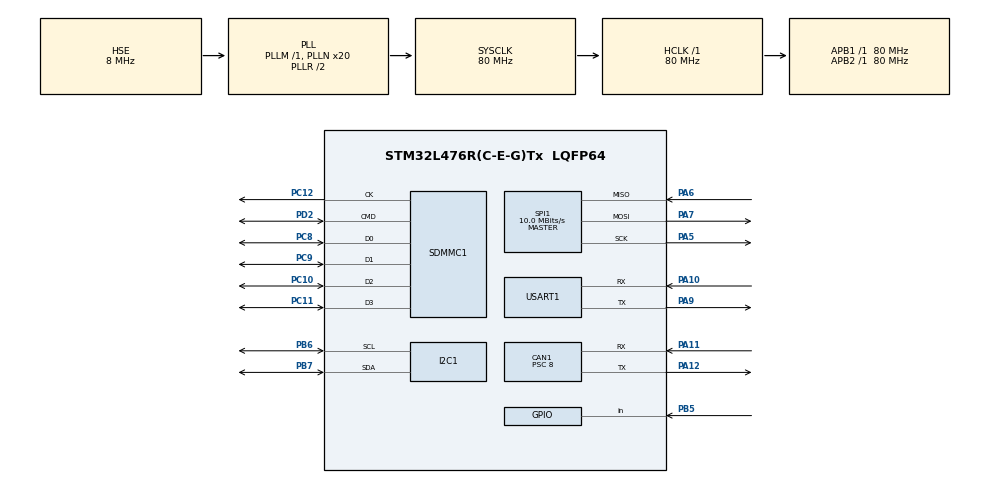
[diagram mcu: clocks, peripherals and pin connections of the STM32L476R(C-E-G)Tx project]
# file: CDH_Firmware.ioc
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CAN1.BS1=CAN_BS1_12TQ
CAN1.BS2=CAN_BS2_3TQ
CAN1.CalculateBaudRate=625000
CAN1.CalculateTimeBit=1600
CAN1.CalculateTimeQuantum=100.0
CAN1.NART=ENABLE
CAN1.Prescaler=8
FATFS.BSP.number=1
FATFS0.BSP.STBoard=false
FATFS0.BSP.api=Unknown
FATFS0.BSP.i2caddr=0
FATFS0.BSP.instance=PB5
FATFS0.BSP.ip=GPIO
FATFS0.BSP.mode=Input
FATFS0.BSP.name=Detect_SDIO
FATFS0.BSP.solution=PB5
FREERTOS.Mutexes01=Config_Mutex,Static,Config_MutexControlBlock;UART_Mutex,Static,UART_MutexControlBlock
FREERTOS.Queues01=CAN_Queue,10,CAN_Event_t,0,Static,CAN_QueueBuffer,CAN_QueueControlBlock;Radio_Queue,8,radio_event_t,0,Static,Radio_QueueBuffer,Radio_QueueControlBlock;GPS_Queue,2,gps_event_t,0,Static,GPS_QueueBuffer,GPS_QueueControlBlock;OBC_Fragment_Queue,8,fragment_t,0,Static,OBC_Fragment_QueueBuffer,OBC_Fragment_QueueControlBlock;RAS_Fragment_Queue,14,fragment_t,0,Static,RAS_Fragment_QueueBuffer,RAS_Fragment_QueueControlBlock;OBC_Blob_Queue,4,obc_blob_t,0,Static,OBC_Blob_QueueBuffer,OBC_Blob_QueueControlBlock;RAS_Blob_Queue,14,ras_blob_t,0,Static,RAS_Blob_QueueBuffer,RAS_Blob_QueueControlBlock
FREERTOS.Tasks01=defaultTask,24,256,StartDefaultTask,Default,NULL,Static,defaultTaskBuffer,defaultTaskControlBlock;CAN_Task,32,256,CAN_TaskFun,As external,NULL,Static,CAN_TaskBuffer,CAN_TaskControlBlock;GPS_Task,8,256,GPS_TaskFun,As external,NULL,Static,GPS_TaskBuffer,GPS_TaskControlBlock;RAS_Blob_Task,8,256,RAS_Blob_TaskFun,As external,NULL,Static,RAS_Blob_TaskBuffer,RAS_Blob_TaskControlBlock;OBC_Blob_Task,8,256,OBC_Blob_TaskFun,As external,NULL,Static,OBC_Blob_TaskBuffer,OBC_Blob_TaskControlBlock;Storage_Task,8,256,Storage_TaskFun,As external,NULL,Static,Storage_TaskBuffer,Storage_TaskControlBlock;PktBuilder_Task,8,256,PktBuilder_TaskFun,As external,NULL,Static,PktBuilder_TaskBuffer,PktBuilder_TaskControlBlock;Radio_Task,8,256,Radio_TaskFun,As external,NULL,Static,Radio_TaskBuffer,Radio_TaskControlBlock;Stimulus_Task,8,256,Stimulus_TaskFun,As external,NULL,Static,Stimulus_TaskBuffer,Stimulus_TaskControlBlock
FREERTOS.Timers01=OBC_Timer,OBC_TimerFun,osTimerPeriodic,As external,NULL,Static,OBC_TimerControlBlock;RAS_Timer,RAS_TimerFun,osTimerPeriodic,As external,NULL,Static,RAS_TimerControlBlock;Radio_Timer,Radio_TimerFun,osTimerPeriodic,As external,NULL,Static,Radio_TimerControlBlock;GPS_Timer,GPS_TimerFun,osTimerPeriodic,As external,NULL,Static,GPS_TimerControlBlock
FREERTOS.configMINIMAL_STACK_SIZE=256
FREERTOS.configUSE_NEWLIB_REENTRANT=1
FREERTOS.configUSE_TICKLESS_IDLE=1
I2C1.Timing=0x10909CEC
Mcu.Family=STM32L4
Mcu.Name=STM32L476R(C-E-G)Tx
Mcu.Package=LQFP64
NVIC.CAN1_RX0_IRQn=true\:5\:0\:false\:false\:true\:true\:true\:true
NVIC.CAN1_TX_IRQn=true\:5\:0\:false\:false\:true\:true\:true\:true
NVIC.PriorityGroup=NVIC_PRIORITYGROUP_4
PA10.Mode=Asynchronous
PA10.Signal=USART1_RX
PA11.Mode=CAN_Activate
PA11.Signal=CAN1_RX
PA12.Mode=CAN_Activate
PA12.Signal=CAN1_TX
PA13\ (JTMS-SWDIO).Mode=Serial_Wire
PA13\ (JTMS-SWDIO).Signal=SYS_JTMS-SWDIO
PA14\ (JTCK-SWCLK).Mode=Serial_Wire
PA14\ (JTCK-SWCLK).Signal=SYS_JTCK-SWCLK
PA5.Mode=Full_Duplex_Master
PA5.Signal=SPI1_SCK
PA6.Mode=Full_Duplex_Master
PA6.Signal=SPI1_MISO
PA7.Mode=Full_Duplex_Master
PA7.Signal=SPI1_MOSI
PA9.Mode=Asynchronous
PA9.Signal=USART1_TX
PB5.Signal=GPIO_Input
PB6.Mode=I2C
PB6.Signal=I2C1_SCL
PB7.Mode=I2C
PB7.Signal=I2C1_SDA
PC10.Mode=SD_4_bits_Wide_bus
PC10.Signal=SDMMC1_D2
PC11.Mode=SD_4_bits_Wide_bus
PC11.Signal=SDMMC1_D3
PC12.Mode=SD_4_bits_Wide_bus
PC12.Signal=SDMMC1_CK
PC14-OSC32_IN\ (PC14).Mode=LSE-External-Oscillator
PC14-OSC32_IN\ (PC14).Signal=RCC_OSC32_IN
PC15-OSC32_OUT\ (PC15).Mode=LSE-External-Oscillator
PC15-OSC32_OUT\ (PC15).Signal=RCC_OSC32_OUT
PC8.Mode=SD_4_bits_Wide_bus
PC8.Signal=SDMMC1_D0
PC9.Mode=SD_4_bits_Wide_bus
PC9.Signal=SDMMC1_D1
PD2.Mode=SD_4_bits_Wide_bus
PD2.Signal=SDMMC1_CMD
PH0-OSC_IN\ (PH0).Mode=HSE-External-Oscillator
PH0-OSC_IN\ (PH0).Signal=RCC_OSC_IN
PH1-OSC_OUT\ (PH1).Mode=HSE-External-Oscillator
PH1-OSC_OUT\ (PH1).Signal=RCC_OSC_OUT
ProjectManager.HeapSize=0x200
ProjectManager.StackSize=0x400
ProjectManager.TargetToolchain=STM32CubeIDE
RCC.ADCFreq_Value=32000000
RCC.AHBFreq_Value=80000000
RCC.APB1Freq_Value=80000000
RCC.APB1TimFreq_Value=80000000
RCC.APB2Freq_Value=80000000
RCC.APB2TimFreq_Value=80000000
RCC.CortexFreq_Value=80000000
RCC.EnableCSSLSE=true
RCC.EnbaleCSS=true
RCC.HCLKFreq_Value=80000000
RCC.HSE_VALUE=8000000
RCC.HSI_VALUE=16000000
RCC.MSI_VALUE=4000000
RCC.PLLN=20
RCC.PLLSourceVirtual=RCC_PLLSOURCE_HSE
RCC.RTCClockSelection=RCC_RTCCLKSOURCE_LSE
RCC.SYSCLKFreq_VALUE=80000000
RCC.SYSCLKSource=RCC_SYSCLKSOURCE_PLLCLK
RCC.USBFreq_Value=32000000
RCC.VCOOutputFreq_Value=160000000
SPI1.BaudRatePrescaler=SPI_BAUDRATEPRESCALER_8
SPI1.CalculateBaudRate=10.0 MBits/s
SPI1.Direction=SPI_DIRECTION_2LINES
SPI1.Mode=SPI_MODE_MASTER
SPI1.VirtualType=VM_MASTER
USART1.VirtualMode-Asynchronous=VM_ASYNC
VP_FATFS_VS_SDIO.Mode=SDIO
VP_FREERTOS_VS_CMSIS_V2.Mode=CMSIS_V2
VP_RTC_VS_RTC_Activate.Mode=RTC_Enabled
board=custom

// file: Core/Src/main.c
/* USER CODE BEGIN Header */
/**
  ******************************************************************************
  * @file           : main.c
  * @brief          : Main program body
  ******************************************************************************
  * @attention
  *
  * Copyright (c) 2022 STMicroelectronics.
  * All rights reserved.
  *
  * This software is licensed under terms that can be found in the LICENSE file
  * in the root directory of this software component.
  * If no LICENSE file comes with this software, it is provided AS-IS.
  *
  ******************************************************************************
  */
/* USER CODE END Header */
#include "main.h"
#include "cmsis_os.h"
#include "can.h"
#include "fatfs.h"
#include "i2c.h"
#include "rtc.h"
#include "sdmmc.h"
#include "spi.h"
#include "usart.h"
#include "gpio.h"

void SystemClock_Config(void);
void MX_FREERTOS_Init(void);

int main(void)
{

  /* MCU Configuration--------------------------------------------------------*/

  /* Reset of all peripherals, Initializes the Flash interface and the Systick. */
  HAL_Init();

  /* Configure the system clock */
  SystemClock_Config();

  /* Initialize all configured peripherals */
  MX_GPIO_Init();
  MX_RTC_Init();
  MX_CAN1_Init();
  MX_I2C1_Init();
  MX_SDMMC1_SD_Init();
  MX_SPI1_Init();
  MX_USART1_UART_Init();
  MX_FATFS_Init();

  /* Init scheduler */
  osKernelInitialize();  /* Call init function for freertos objects (in freertos.c) */
  MX_FREERTOS_Init();
  /* Start scheduler */
  osKernelStart();

  /* We should never get here as control is now taken by the scheduler */
  /* Infinite loop */
  while (1)
  {

  }
}

void SystemClock_Config(void)
{
  RCC_OscInitTypeDef RCC_OscInitStruct = {0};
  RCC_ClkInitTypeDef RCC_ClkInitStruct = {0};

  /** Configure the main internal regulator output voltage
  */
  if (HAL_PWREx_ControlVoltageScaling(PWR_REGULATOR_VOLTAGE_SCALE1) != HAL_OK)
  {
    Error_Handler();
  }
  /** Configure LSE Drive Capability
  */
  HAL_PWR_EnableBkUpAccess();
  __HAL_RCC_LSEDRIVE_CONFIG(RCC_LSEDRIVE_LOW);
  /** Initializes the RCC Oscillators according to the specified parameters
  * in the RCC_OscInitTypeDef structure.
  */
  RCC_OscInitStruct.OscillatorType = RCC_OSCILLATORTYPE_HSE|RCC_OSCILLATORTYPE_LSE;
  RCC_OscInitStruct.HSEState = RCC_HSE_ON;
  RCC_OscInitStruct.LSEState = RCC_LSE_ON;
  RCC_OscInitStruct.PLL.PLLState = RCC_PLL_ON;
  RCC_OscInitStruct.PLL.PLLSource = RCC_PLLSOURCE_HSE;
  RCC_OscInitStruct.PLL.PLLM = 1;
  RCC_OscInitStruct.PLL.PLLN = 20;
  RCC_OscInitStruct.PLL.PLLP = RCC_PLLP_DIV7;
  RCC_OscInitStruct.PLL.PLLQ = RCC_PLLQ_DIV2;
  RCC_OscInitStruct.PLL.PLLR = RCC_PLLR_DIV2;
  if (HAL_RCC_OscConfig(&RCC_OscInitStruct) != HAL_OK)
  {
    Error_Handler();
  }
  /** Initializes the CPU, AHB and APB buses clocks
  */
  RCC_ClkInitStruct.ClockType = RCC_CLOCKTYPE_HCLK|RCC_CLOCKTYPE_SYSCLK
                              |RCC_CLOCKTYPE_PCLK1|RCC_CLOCKTYPE_PCLK2;
  RCC_ClkInitStruct.SYSCLKSource = RCC_SYSCLKSOURCE_PLLCLK;
  RCC_ClkInitStruct.AHBCLKDivider = RCC_SYSCLK_DIV1;
  RCC_ClkInitStruct.APB1CLKDivider = RCC_HCLK_DIV1;
  RCC_ClkInitStruct.APB2CLKDivider = RCC_HCLK_DIV1;

  if (HAL_RCC_ClockConfig(&RCC_ClkInitStruct, FLASH_LATENCY_4) != HAL_OK)
  {
    Error_Handler();
  }
  /** Enables the Clock Security System
  */
  HAL_RCC_EnableCSS();
  /** Enables the Clock Security System
  */
  HAL_RCCEx_EnableLSECSS();
}

void Error_Handler(void)
{
  __disable_irq();
  while (1)
  {
  }
}

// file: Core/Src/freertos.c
/* USER CODE BEGIN Header */
/**
  ******************************************************************************
  * File Name          : freertos.c
  * Description        : Code for freertos applications
  ******************************************************************************
  * @attention
  *
  * Copyright (c) 2022 STMicroelectronics.
  * All rights reserved.
  *
  * This software is licensed under terms that can be found in the LICENSE file
  * in the root directory of this software component.
  * If no LICENSE file comes with this software, it is provided AS-IS.
  *
  ******************************************************************************
  */
/* USER CODE END Header */

#include "FreeRTOS.h"
#include "task.h"
#include "main.h"
#include "cmsis_os.h"

/* USER CODE BEGIN Includes */
#include "CDH.h"
/* USER CODE END Includes */

typedef StaticTask_t osStaticThreadDef_t;
typedef StaticQueue_t osStaticMessageQDef_t;
typedef StaticTimer_t osStaticTimerDef_t;
typedef StaticSemaphore_t osStaticMutexDef_t;

/* Definitions for defaultTask */
osThreadId_t defaultTaskHandle;
uint32_t defaultTaskBuffer[ 256 ];
osStaticThreadDef_t defaultTaskControlBlock;
const osThreadAttr_t defaultTask_attributes = {
  .name = "defaultTask",
  .cb_mem = &defaultTaskControlBlock,
  .cb_size = sizeof(defaultTaskControlBlock),
  .stack_mem = &defaultTaskBuffer[0],
  .stack_size = sizeof(defaultTaskBuffer),
  .priority = (osPriority_t) osPriorityNormal,
};
/* Definitions for CAN_Task */
osThreadId_t CAN_TaskHandle;
uint32_t CAN_TaskBuffer[ 256 ];
osStaticThreadDef_t CAN_TaskControlBlock;
const osThreadAttr_t CAN_Task_attributes = {
  .name = "CAN_Task",
  .cb_mem = &CAN_TaskControlBlock,
  .cb_size = sizeof(CAN_TaskControlBlock),
  .stack_mem = &CAN_TaskBuffer[0],
  .stack_size = sizeof(CAN_TaskBuffer),
  .priority = (osPriority_t) osPriorityAboveNormal,
};
/* Definitions for GPS_Task */
osThreadId_t GPS_TaskHandle;
uint32_t GPS_TaskBuffer[ 256 ];
osStaticThreadDef_t GPS_TaskControlBlock;
const osThreadAttr_t GPS_Task_attributes = {
  .name = "GPS_Task",
  .cb_mem = &GPS_TaskControlBlock,
  .cb_size = sizeof(GPS_TaskControlBlock),
  .stack_mem = &GPS_TaskBuffer[0],
  .stack_size = sizeof(GPS_TaskBuffer),
  .priority = (osPriority_t) osPriorityLow,
};
/* Definitions for RAS_Blob_Task */
osThreadId_t RAS_Blob_TaskHandle;
uint32_t RAS_Blob_TaskBuffer[ 256 ];
osStaticThreadDef_t RAS_Blob_TaskControlBlock;
const osThreadAttr_t RAS_Blob_Task_attributes = {
  .name = "RAS_Blob_Task",
  .cb_mem = &RAS_Blob_TaskControlBlock,
  .cb_size = sizeof(RAS_Blob_TaskControlBlock),
  .stack_mem = &RAS_Blob_TaskBuffer[0],
  .stack_size = sizeof(RAS_Blob_TaskBuffer),
  .priority = (osPriority_t) osPriorityLow,
};
/* Definitions for OBC_Blob_Task */
osThreadId_t OBC_Blob_TaskHandle;
uint32_t OBC_Blob_TaskBuffer[ 256 ];
osStaticThreadDef_t OBC_Blob_TaskControlBlock;
const osThreadAttr_t OBC_Blob_Task_attributes = {
  .name = "OBC_Blob_Task",
  .cb_mem = &OBC_Blob_TaskControlBlock,
  .cb_size = sizeof(OBC_Blob_TaskControlBlock),
  .stack_mem = &OBC_Blob_TaskBuffer[0],
  .stack_size = sizeof(OBC_Blob_TaskBuffer),
  .priority = (osPriority_t) osPriorityLow,
};
/* Definitions for Storage_Task */
osThreadId_t Storage_TaskHandle;
uint32_t Storage_TaskBuffer[ 256 ];
osStaticThreadDef_t Storage_TaskControlBlock;
const osThreadAttr_t Storage_Task_attributes = {
  .name = "Storage_Task",
  .cb_mem = &Storage_TaskControlBlock,
  .cb_size = sizeof(Storage_TaskControlBlock),
  .stack_mem = &Storage_TaskBuffer[0],
  .stack_size = sizeof(Storage_TaskBuffer),
  .priority = (osPriority_t) osPriorityLow,
};
/* Definitions for PktBuilder_Task */
osThreadId_t PktBuilder_TaskHandle;
uint32_t PktBuilder_TaskBuffer[ 256 ];
osStaticThreadDef_t PktBuilder_TaskControlBlock;
const osThreadAttr_t PktBuilder_Task_attributes = {
  .name = "PktBuilder_Task",
  .cb_mem = &PktBuilder_TaskControlBlock,
  .cb_size = sizeof(PktBuilder_TaskControlBlock),
  .stack_mem = &PktBuilder_TaskBuffer[0],
  .stack_size = sizeof(PktBuilder_TaskBuffer),
  .priority = (osPriority_t) osPriorityLow,
};
/* Definitions for Radio_Task */
osThreadId_t Radio_TaskHandle;
uint32_t Radio_TaskBuffer[ 256 ];
osStaticThreadDef_t Radio_TaskControlBlock;
const osThreadAttr_t Radio_Task_attributes = {
  .name = "Radio_Task",
  .cb_mem = &Radio_TaskControlBlock,
  .cb_size = sizeof(Radio_TaskControlBlock),
  .stack_mem = &Radio_TaskBuffer[0],
  .stack_size = sizeof(Radio_TaskBuffer),
  .priority = (osPriority_t) osPriorityLow,
};
/* Definitions for Stimulus_Task */
osThreadId_t Stimulus_TaskHandle;
uint32_t Stimulus_TaskBuffer[ 256 ];
osStaticThreadDef_t Stimulus_TaskControlBlock;
const osThreadAttr_t Stimulus_Task_attributes = {
  .name = "Stimulus_Task",
  .cb_mem = &Stimulus_TaskControlBlock,
  .cb_size = sizeof(Stimulus_TaskControlBlock),
  .stack_mem = &Stimulus_TaskBuffer[0],
  .stack_size = sizeof(Stimulus_TaskBuffer),
  .priority = (osPriority_t) osPriorityLow,
};
/* Definitions for CAN_Queue */
osMessageQueueId_t CAN_QueueHandle;
uint8_t CAN_QueueBuffer[ 10 * sizeof( CAN_Event_t ) ];
osStaticMessageQDef_t CAN_QueueControlBlock;
const osMessageQueueAttr_t CAN_Queue_attributes = {
  .name = "CAN_Queue",
  .cb_mem = &CAN_QueueControlBlock,
  .cb_size = sizeof(CAN_QueueControlBlock),
  .mq_mem = &CAN_QueueBuffer,
  .mq_size = sizeof(CAN_QueueBuffer)
};
/* Definitions for Radio_Queue */
osMessageQueueId_t Radio_QueueHandle;
uint8_t Radio_QueueBuffer[ 8 * sizeof( radio_event_t ) ];
osStaticMessageQDef_t Radio_QueueControlBlock;
const osMessageQueueAttr_t Radio_Queue_attributes = {
  .name = "Radio_Queue",
  .cb_mem = &Radio_QueueControlBlock,
  .cb_size = sizeof(Radio_QueueControlBlock),
  .mq_mem = &Radio_QueueBuffer,
  .mq_size = sizeof(Radio_QueueBuffer)
};
/* Definitions for GPS_Queue */
osMessageQueueId_t GPS_QueueHandle;
uint8_t GPS_QueueBuffer[ 2 * sizeof( gps_event_t ) ];
osStaticMessageQDef_t GPS_QueueControlBlock;
const osMessageQueueAttr_t GPS_Queue_attributes = {
  .name = "GPS_Queue",
  .cb_mem = &GPS_QueueControlBlock,
  .cb_size = sizeof(GPS_QueueControlBlock),
  .mq_mem = &GPS_QueueBuffer,
  .mq_size = sizeof(GPS_QueueBuffer)
};
/* Definitions for OBC_Fragment_Queue */
osMessageQueueId_t OBC_Fragment_QueueHandle;
uint8_t OBC_Fragment_QueueBuffer[ 8 * sizeof( fragment_t ) ];
osStaticMessageQDef_t OBC_Fragment_QueueControlBlock;
const osMessageQueueAttr_t OBC_Fragment_Queue_attributes = {
  .name = "OBC_Fragment_Queue",
  .cb_mem = &OBC_Fragment_QueueControlBlock,
  .cb_size = sizeof(OBC_Fragment_QueueControlBlock),
  .mq_mem = &OBC_Fragment_QueueBuffer,
  .mq_size = sizeof(OBC_Fragment_QueueBuffer)
};
/* Definitions for RAS_Fragment_Queue */
osMessageQueueId_t RAS_Fragment_QueueHandle;
uint8_t RAS_Fragment_QueueBuffer[ 14 * sizeof( fragment_t ) ];
osStaticMessageQDef_t RAS_Fragment_QueueControlBlock;
const osMessageQueueAttr_t RAS_Fragment_Queue_attributes = {
  .name = "RAS_Fragment_Queue",
  .cb_mem = &RAS_Fragment_QueueControlBlock,
  .cb_size = sizeof(RAS_Fragment_QueueControlBlock),
  .mq_mem = &RAS_Fragment_QueueBuffer,
  .mq_size = sizeof(RAS_Fragment_QueueBuffer)
};
/* Definitions for OBC_Blob_Queue */
osMessageQueueId_t OBC_Blob_QueueHandle;
uint8_t OBC_Blob_QueueBuffer[ 4 * sizeof( obc_blob_t ) ];
osStaticMessageQDef_t OBC_Blob_QueueControlBlock;
const osMessageQueueAttr_t OBC_Blob_Queue_attributes = {
  .name = "OBC_Blob_Queue",
  .cb_mem = &OBC_Blob_QueueControlBlock,
  .cb_size = sizeof(OBC_Blob_QueueControlBlock),
  .mq_mem = &OBC_Blob_QueueBuffer,
  .mq_size = sizeof(OBC_Blob_QueueBuffer)
};
/* Definitions for RAS_Blob_Queue */
osMessageQueueId_t RAS_Blob_QueueHandle;
uint8_t RAS_Blob_QueueBuffer[ 14 * sizeof( ras_blob_t ) ];
osStaticMessageQDef_t RAS_Blob_QueueControlBlock;
const osMessageQueueAttr_t RAS_Blob_Queue_attributes = {
  .name = "RAS_Blob_Queue",
  .cb_mem = &RAS_Blob_QueueControlBlock,
  .cb_size = sizeof(RAS_Blob_QueueControlBlock),
  .mq_mem = &RAS_Blob_QueueBuffer,
  .mq_size = sizeof(RAS_Blob_QueueBuffer)
};
/* Definitions for OBC_Timer */
osTimerId_t OBC_TimerHandle;
osStaticTimerDef_t OBC_TimerControlBlock;
const osTimerAttr_t OBC_Timer_attributes = {
  .name = "OBC_Timer",
  .cb_mem = &OBC_TimerControlBlock,
  .cb_size = sizeof(OBC_TimerControlBlock),
};
/* Definitions for RAS_Timer */
osTimerId_t RAS_TimerHandle;
osStaticTimerDef_t RAS_TimerControlBlock;
const osTimerAttr_t RAS_Timer_attributes = {
  .name = "RAS_Timer",
  .cb_mem = &RAS_TimerControlBlock,
  .cb_size = sizeof(RAS_TimerControlBlock),
};
/* Definitions for Radio_Timer */
osTimerId_t Radio_TimerHandle;
osStaticTimerDef_t Radio_TimerControlBlock;
const osTimerAttr_t Radio_Timer_attributes = {
  .name = "Radio_Timer",
  .cb_mem = &Radio_TimerControlBlock,
  .cb_size = sizeof(Radio_TimerControlBlock),
};
/* Definitions for GPS_Timer */
osTimerId_t GPS_TimerHandle;
osStaticTimerDef_t GPS_TimerControlBlock;
const osTimerAttr_t GPS_Timer_attributes = {
  .name = "GPS_Timer",
  .cb_mem = &GPS_TimerControlBlock,
  .cb_size = sizeof(GPS_TimerControlBlock),
};
/* Definitions for Config_Mutex */
osMutexId_t Config_MutexHandle;
osStaticMutexDef_t Config_MutexControlBlock;
const osMutexAttr_t Config_Mutex_attributes = {
  .name = "Config_Mutex",
  .cb_mem = &Config_MutexControlBlock,
  .cb_size = sizeof(Config_MutexControlBlock),
};
/* Definitions for UART_Mutex */
osMutexId_t UART_MutexHandle;
osStaticMutexDef_t UART_MutexControlBlock;
const osMutexAttr_t UART_Mutex_attributes = {
  .name = "UART_Mutex",
  .cb_mem = &UART_MutexControlBlock,
  .cb_size = sizeof(UART_MutexControlBlock),
};

void StartDefaultTask(void *argument);
extern void CAN_TaskFun(void *argument);
extern void GPS_TaskFun(void *argument);
extern void RAS_Blob_TaskFun(void *argument);
extern void OBC_Blob_TaskFun(void *argument);
extern void Storage_TaskFun(void *argument);
extern void PktBuilder_TaskFun(void *argument);
extern void Radio_TaskFun(void *argument);
extern void Stimulus_TaskFun(void *argument);
extern void OBC_TimerFun(void *argument);
extern void RAS_TimerFun(void *argument);
extern void Radio_TimerFun(void *argument);
extern void GPS_TimerFun(void *argument);

void MX_FREERTOS_Init(void); /* (MISRA C 2004 rule 8.1) */

/* USER CODE BEGIN PREPOSTSLEEP */
__weak void PreSleepProcessing(uint32_t ulExpectedIdleTime)
{
/* place for user code */
}

__weak void PostSleepProcessing(uint32_t ulExpectedIdleTime)
{
/* place for user code */
}
/* USER CODE END PREPOSTSLEEP */

void MX_FREERTOS_Init(void) {
  /* Create the mutex(es) */
  /* creation of Config_Mutex */
  Config_MutexHandle = osMutexNew(&Config_Mutex_attributes);

  /* creation of UART_Mutex */
  UART_MutexHandle = osMutexNew(&UART_Mutex_attributes);

  /* Create the timer(s) */
  /* creation of OBC_Timer */
  OBC_TimerHandle = osTimerNew(OBC_TimerFun, osTimerPeriodic, NULL, &OBC_Timer_attributes);

  /* creation of RAS_Timer */
  RAS_TimerHandle = osTimerNew(RAS_TimerFun, osTimerPeriodic, NULL, &RAS_Timer_attributes);

  /* creation of Radio_Timer */
  Radio_TimerHandle = osTimerNew(Radio_TimerFun, osTimerPeriodic, NULL, &Radio_Timer_attributes);

  /* creation of GPS_Timer */
  GPS_TimerHandle = osTimerNew(GPS_TimerFun, osTimerPeriodic, NULL, &GPS_Timer_attributes);

  /* Create the queue(s) */
  /* creation of CAN_Queue */
  CAN_QueueHandle = osMessageQueueNew (10, sizeof(CAN_Event_t), &CAN_Queue_attributes);

  /* creation of Radio_Queue */
  Radio_QueueHandle = osMessageQueueNew (8, sizeof(radio_event_t), &Radio_Queue_attributes);

  /* creation of GPS_Queue */
  GPS_QueueHandle = osMessageQueueNew (2, sizeof(gps_event_t), &GPS_Queue_attributes);

  /* creation of OBC_Fragment_Queue */
  OBC_Fragment_QueueHandle = osMessageQueueNew (8, sizeof(fragment_t), &OBC_Fragment_Queue_attributes);

  /* creation of RAS_Fragment_Queue */
  RAS_Fragment_QueueHandle = osMessageQueueNew (14, sizeof(fragment_t), &RAS_Fragment_Queue_attributes);

  /* creation of OBC_Blob_Queue */
  OBC_Blob_QueueHandle = osMessageQueueNew (4, sizeof(obc_blob_t), &OBC_Blob_Queue_attributes);

  /* creation of RAS_Blob_Queue */
  RAS_Blob_QueueHandle = osMessageQueueNew (14, sizeof(ras_blob_t), &RAS_Blob_Queue_attributes);

  /* Create the thread(s) */
  /* creation of defaultTask */
  defaultTaskHandle = osThreadNew(StartDefaultTask, NULL, &defaultTask_attributes);

  /* creation of CAN_Task */
  CAN_TaskHandle = osThreadNew(CAN_TaskFun, NULL, &CAN_Task_attributes);

  /* creation of GPS_Task */
  GPS_TaskHandle = osThreadNew(GPS_TaskFun, NULL, &GPS_Task_attributes);

  /* creation of RAS_Blob_Task */
  RAS_Blob_TaskHandle = osThreadNew(RAS_Blob_TaskFun, NULL, &RAS_Blob_Task_attributes);

  /* creation of OBC_Blob_Task */
  OBC_Blob_TaskHandle = osThreadNew(OBC_Blob_TaskFun, NULL, &OBC_Blob_Task_attributes);

  /* creation of Storage_Task */
  Storage_TaskHandle = osThreadNew(Storage_TaskFun, NULL, &Storage_Task_attributes);

  /* creation of PktBuilder_Task */
  PktBuilder_TaskHandle = osThreadNew(PktBuilder_TaskFun, NULL, &PktBuilder_Task_attributes);

  /* creation of Radio_Task */
  Radio_TaskHandle = osThreadNew(Radio_TaskFun, NULL, &Radio_Task_attributes);

  /* creation of Stimulus_Task */
  Stimulus_TaskHandle = osThreadNew(Stimulus_TaskFun, NULL, &Stimulus_Task_attributes);

}

void StartDefaultTask(void *argument)
{
  for(;;)
  {
    osDelay(1);
  }
}
